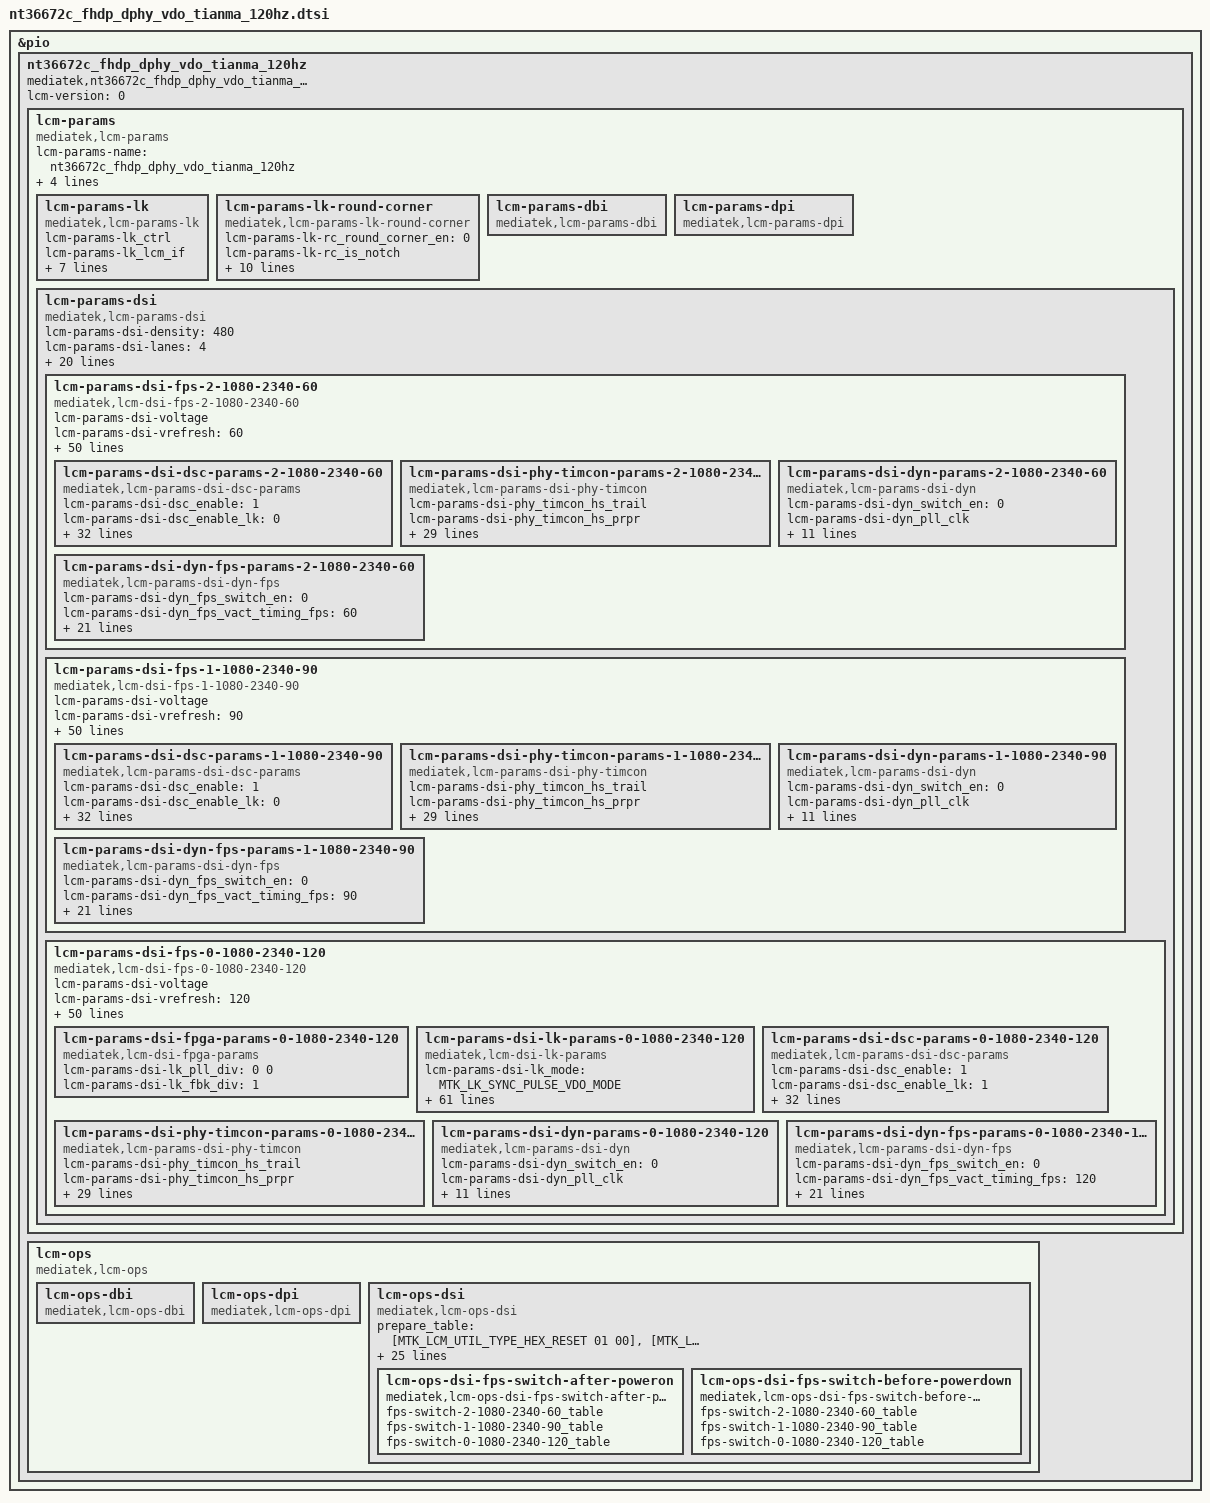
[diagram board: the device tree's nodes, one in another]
// SPDX-License-Identifier: GPL-2.0
/*
 * Device Tree defines for LCM settings
 * Copyright (c) 2021 MediaTek Inc.
 */

#include "mtk_lcm_settings.h"

&pio {
	nt36672c_fhdp_dphy_vdo_tianma_120hz: nt36672c_fhdp_dphy_vdo_tianma_120hz {
		compatible = "mediatek,nt36672c_fhdp_dphy_vdo_tianma_120hz";
		lcm-version = <0>;

		lcm-params{
			compatible = "mediatek,lcm-params";
			lcm-params-name = "nt36672c_fhdp_dphy_vdo_tianma_120hz";
			lcm-params-types = <MTK_LCM_FUNC_DSI>;
			lcm-params-resolution = <1080 2340>;
			lcm-params-physical_width = <68>;
			lcm-params-physical_height = <152>;

			/* lk support */
			lcm-params-lk {
				compatible = "mediatek,lcm-params-lk";
				lcm-params-lk_ctrl;
				lcm-params-lk_lcm_if;
				lcm-params-lk_lcm_cmd_if;
				lcm-params-lk_io_select_mode;
				lcm-params-lk_lcm_x;
				lcm-params-lk_lcm_y;
				lcm-params-lk_virtual_resolution = <0 0>;
				lcm-params-lk_od_table_size;
				lcm-params-lk_od_table;
			};

			lcm-params-lk-round-corner {
				compatible = "mediatek,lcm-params-lk-round-corner";
				lcm-params-lk-rc_round_corner_en = <0>;
				lcm-params-lk-rc_is_notch;
				lcm-params-lk-rc_full_content = <0>;
				lcm-params-lk-rc_width;
				lcm-params-lk-rc_height;
				lcm-params-lk-rc_width_bot;
				lcm-params-lk-rc_height_bot;
				lcm-params-lk-rc_top_size;
				lcm-params-lk-rc_top_size_left;
				lcm-params-lk-rc_top_size_right;
				lcm-params-lk-rc_bottom_size;
				lcm-params-lk-rc_pattern_name;
			};

			lcm-params-dbi {
				compatible = "mediatek,lcm-params-dbi";
				/* future reserved for dbi interfaces */
			};

			lcm-params-dpi {
				compatible = "mediatek,lcm-params-dpi";
				/* future reserved for dpi interfaces */
			};

			lcm-params-dsi {
				compatible = "mediatek,lcm-params-dsi";
				lcm-params-dsi-density = <480>;
				lcm-params-dsi-lanes = <4>;
				lcm-params-dsi-format = <MTK_MIPI_DSI_FMT_RGB888>;
				lcm-params-dsi-phy_type = <MTK_LCM_MIPI_DPHY>;
				lcm-params-dsi-mode_flags = <MTK_MIPI_DSI_MODE_VIDEO>,
						<MTK_MIPI_DSI_MODE_VIDEO_SYNC_PULSE>,
						<MTK_MIPI_DSI_MODE_LPM>,
						<MTK_MIPI_DSI_MODE_EOT_PACKET>,
						<MTK_MIPI_DSI_CLOCK_NON_CONTINUOUS>;
				lcm-params-dsi-mode_flags_doze_on;
				lcm-params-dsi-mode_flags_doze_off;

				lcm-params-dsi-need_fake_resolution;
				lcm-params-dsi-fake_resolution = <1080 2340>;

				lcm_gpio_list = <&pio 42 0>, /* gpio list*/
					<&pio 28 0>,
					<&pio 29 0>;
				pinctrl-names = "gpio1", "gpio2", "gpio3";
				pinctrl-0;
				pinctrl-1;
				pinctrl-2;
				status = "okay";

				lcm-params-dsi-default_mode = <0>;
				lcm-params-dsi-mode_count = <3>;
				lcm-params-dsi-mode_list =
					<0 1080 2340 120>,
					<1 1080 2340 90>,
					<2 1080 2340 60>;

				lcm-params-dsi-fps-2-1080-2340-60 {
					compatible = "mediatek,lcm-dsi-fps-2-1080-2340-60";
					lcm-params-dsi-voltage;

					/* drm_display_mode */
					lcm-params-dsi-vrefresh = <60>;
					lcm-params-dsi-vertical_sync_active = <10>;
					lcm-params-dsi-vertical_backporch = <25>;
					lcm-params-dsi-vertical_frontporch = <2380>;
					lcm-params-dsi-vertical_active_line = <2340>;
					lcm-params-dsi-horizontal_sync_active = <20>;
					lcm-params-dsi-horizontal_backporch = <80>;
					lcm-params-dsi-horizontal_frontporch = <80>;
					lcm-params-dsi-horizontal_active_pixel = <1080>;
					lcm-params-dsi-pixel_clock = <361519>;
					lcm-params-dsi-hskew;
					lcm-params-dsi-vscan;

					/* mtk_panel_params */
					lcm-params-dsi-pll_clock = <535>;
					lcm-params-dsi-data_rate = <1070>;
					lcm-params-dsi-vfp_for_low_power = <4205>;
					lcm-params-dsi-ssc_disable;
					lcm-params-dsi-ssc_range;
					lcm-params-dsi-lcm_color_mode;
					lcm-params-dsi-min_luminance;
					lcm-params-dsi-average_luminance;
					lcm-params-dsi-max_luminance;
					lcm-params-dsi-round_corner_en = <0>;
					lcm-params-dsi-corner_pattern_height;
					lcm-params-dsi-corner_pattern_height_bot;
					lcm-params-dsi-corner_pattern_tp_size;
					lcm-params-dsi-corner_pattern_tp_size_left;
					lcm-params-dsi-corner_pattern_tp_size_right;
					lcm-params-dsi-corner_pattern_name;
					lcm-params-dsi-physical_width_um = <68364>;
					lcm-params-dsi-physical_height_um = <152300>;
					lcm-params-dsi-output_mode =
						<MTK_LCM_PANEL_DSC_SINGLE_PORT>;
					lcm-params-dsi-lcm_cmd_if;
					lcm-params-dsi-hbm_en_time;
					lcm-params-dsi-hbm_dis_time;
					lcm-params-dsi-lcm_index;
					lcm-params-dsi-wait_sof_before_dec_vfp;
					lcm-params-dsi-doze_delay;
					lcm-params-dsi-lfr_enable = <1>;
					lcm-params-dsi-lfr_minimum_fps = <60>;
					lcm-params-dsi-msync2_enable;
					lcm-params-dsi-max_vfp_for_msync;

					/* lane swap */
					lcm-params-dsi-lane_swap_en;
					lcm-params-dsi-lane_swap0;
					lcm-params-dsi-lane_swap1;

					/* esd check table */
					lcm-params-dsi-cust_esd_check = <1>;
					lcm-params-dsi-esd_check_enable = <1>;
					lcm-params-dsi-lcm_esd_check_table0 = [0A 01 9C];
					lcm-params-dsi-lcm_esd_check_table1;
					lcm-params-dsi-lcm_esd_check_table2;

					lcm-params-dsi-dsc-params-2-1080-2340-60 {
						compatible =
							"mediatek,lcm-params-dsi-dsc-params";
						lcm-params-dsi-dsc_enable = <1>;
						lcm-params-dsi-dsc_enable_lk = <0>;
						lcm-params-dsi-dsc_ver = <17>;
						lcm-params-dsi-dsc_slice_mode = <1>;
						lcm-params-dsi-dsc_rgb_swap = <0>;
						lcm-params-dsi-dsc_cfg = <34>;
						lcm-params-dsi-dsc_rct_on = <1>;
						lcm-params-dsi-dsc_bit_per_channel = <8>;
						lcm-params-dsi-dsc_line_buf_depth = <9>;
						lcm-params-dsi-dsc_bp_enable = <1>;
						lcm-params-dsi-dsc_bit_per_pixel = <128>;
						lcm-params-dsi-dsc_pic_height = <2340>;
						lcm-params-dsi-dsc_pic_width = <1080>;
						lcm-params-dsi-dsc_slice_height = <20>;
						lcm-params-dsi-dsc_slice_width = <540>;
						lcm-params-dsi-dsc_chunk_size = <540>;
						lcm-params-dsi-dsc_xmit_delay = <512>;
						lcm-params-dsi-dsc_dec_delay = <526>;
						lcm-params-dsi-dsc_scale_value = <32>;
						lcm-params-dsi-dsc_increment_interval = <488>;
						lcm-params-dsi-dsc_decrement_interval = <7>;
						lcm-params-dsi-dsc_line_bpg_offset = <12>;
						lcm-params-dsi-dsc_nfl_bpg_offset = <1294>;
						lcm-params-dsi-dsc_slice_bpg_offset = <1302>;
						lcm-params-dsi-dsc_initial_offset = <6144>;
						lcm-params-dsi-dsc_final_offset = <4336>;
						lcm-params-dsi-dsc_flatness_minqp = <3>;
						lcm-params-dsi-dsc_flatness_maxqp = <12>;
						lcm-params-dsi-dsc_rc_model_size = <8192>;
						lcm-params-dsi-dsc_rc_edge_factor = <6>;
						lcm-params-dsi-dsc_rc_quant_incr_limit0 = <11>;
						lcm-params-dsi-dsc_rc_quant_incr_limit1 = <11>;
						lcm-params-dsi-dsc_rc_tgt_offset_hi = <3>;
						lcm-params-dsi-dsc_rc_tgt_offset_lo = <3>;
					};

					lcm-params-dsi-phy-timcon-params-2-1080-2340-60 {
						compatible =
							"mediatek,lcm-params-dsi-phy-timcon";
						lcm-params-dsi-phy_timcon_hs_trail;
						lcm-params-dsi-phy_timcon_hs_prpr;
						lcm-params-dsi-phy_timcon_hs_zero;
						lcm-params-dsi-phy_timcon_lpx;
						lcm-params-dsi-phy_timcon_ta_get;
						lcm-params-dsi-phy_timcon_ta_sure;
						lcm-params-dsi-phy_timcon_ta_go;
						lcm-params-dsi-phy_timcon_da_hs_exit;
						lcm-params-dsi-phy_timcon_clk_trail;
						lcm-params-dsi-phy_timcon_cont_det;
						lcm-params-dsi-phy_timcon_da_hs_sync;
						lcm-params-dsi-phy_timcon_clk_zero;
						lcm-params-dsi-phy_timcon_clk_prpr;
						lcm-params-dsi-phy_timcon_clk_exit;
						lcm-params-dsi-phy_timcon_clk_post;

						/* lk support */
						lcm-params-dsi-phy_timcon_lk_hs_trail;
						lcm-params-dsi-phy_timcon_lk_hs_zero;
						lcm-params-dsi-phy_timcon_lk_hs_prpr = <10>;
						lcm-params-dsi-phy_timcon_lk_lpx;
						lcm-params-dsi-phy_timcon_lk_ta_sack;
						lcm-params-dsi-phy_timcon_lk_ta_get;
						lcm-params-dsi-phy_timcon_lk_ta_sure;
						lcm-params-dsi-phy_timcon_lk_ta_go;
						lcm-params-dsi-phy_timcon_lk_clk_trail;
						lcm-params-dsi-phy_timcon_lk_clk_zero;
						lcm-params-dsi-phy_timcon_lk_lpx_wait;
						lcm-params-dsi-phy_timcon_lk_cont_det;
						lcm-params-dsi-phy_timcon_lk_clk_hs_prpr;
						lcm-params-dsi-phy_timcon_lk_clk_hs_post;
						lcm-params-dsi-phy_timcon_lk_da_hs_exit;
						lcm-params-dsi-phy_timcon_lk_clk_hs_exit;
					};

					lcm-params-dsi-dyn-params-2-1080-2340-60 {
						compatible =
							"mediatek,lcm-params-dsi-dyn";
						lcm-params-dsi-dyn_switch_en = <0>;
						lcm-params-dsi-dyn_pll_clk;
						lcm-params-dsi-dyn_data_rate = <1070>;
						lcm-params-dsi-dyn_vsa;
						lcm-params-dsi-dyn_vbp;
						lcm-params-dsi-dyn_vfp = <2528>;
						lcm-params-dsi-dyn_vfp_lp_dyn = <4178>;
						lcm-params-dsi-dyn_vac;
						lcm-params-dsi-dyn_hsa;
						lcm-params-dsi-dyn_hbp;
						lcm-params-dsi-dyn_hfp;
						lcm-params-dsi-dyn_hac;
						lcm-params-dsi-dyn_max_vfp_for_msync_dyn;
					};

					lcm-params-dsi-dyn-fps-params-2-1080-2340-60 {
						compatible =
							"mediatek,lcm-params-dsi-dyn-fps";
						lcm-params-dsi-dyn_fps_switch_en = <0>;
						lcm-params-dsi-dyn_fps_vact_timing_fps = <60>;
						lcm-params-dsi-dyn_fps_data_rate;
						lcm-params-dsi-dyn_fps_dfps_cmd_table0;
						lcm-params-dsi-dyn_fps_dfps_cmd_table1;
						lcm-params-dsi-dyn_fps_dfps_cmd_table2;
						lcm-params-dsi-dyn_fps_dfps_cmd_table3;
						lcm-params-dsi-dyn_fps_dfps_cmd_table4;
						lcm-params-dsi-dyn_fps_dfps_cmd_table5;
						lcm-params-dsi-dyn_fps_dfps_cmd_table6;
						lcm-params-dsi-dyn_fps_dfps_cmd_table7;
						lcm-params-dsi-dyn_fps_dfps_cmd_table8;
						lcm-params-dsi-dyn_fps_dfps_cmd_table9;
						lcm-params-dsi-dyn_fps_dfps_cmd_table10;
						lcm-params-dsi-dyn_fps_dfps_cmd_table11;
						lcm-params-dsi-dyn_fps_dfps_cmd_table12;
						lcm-params-dsi-dyn_fps_dfps_cmd_table13;
						lcm-params-dsi-dyn_fps_dfps_cmd_table14;
						lcm-params-dsi-dyn_fps_dfps_cmd_table15;
						lcm-params-dsi-dyn_fps_dfps_cmd_table16;
						lcm-params-dsi-dyn_fps_dfps_cmd_table17;
						lcm-params-dsi-dyn_fps_dfps_cmd_table18;
						lcm-params-dsi-dyn_fps_dfps_cmd_table19;
					};
				};

				lcm-params-dsi-fps-1-1080-2340-90 {
					compatible = "mediatek,lcm-dsi-fps-1-1080-2340-90";
					lcm-params-dsi-voltage;

					/* drm_display_mode */
					lcm-params-dsi-vrefresh = <90>;
					lcm-params-dsi-vertical_sync_active = <10>;
					lcm-params-dsi-vertical_backporch = <25>;
					lcm-params-dsi-vertical_frontporch = <810>;
					lcm-params-dsi-vertical_active_line = <2340>;
					lcm-params-dsi-horizontal_sync_active = <20>;
					lcm-params-dsi-horizontal_backporch = <80>;
					lcm-params-dsi-horizontal_frontporch = <80>;
					lcm-params-dsi-horizontal_active_pixel = <1080>;
					lcm-params-dsi-pixel_clock = <361519>;
					lcm-params-dsi-hskew;
					lcm-params-dsi-vscan;

					/* mtk_panel_params */
					lcm-params-dsi-pll_clock = <535>;
					lcm-params-dsi-data_rate = <1070>;
					lcm-params-dsi-vfp_for_low_power = <2546>;
					lcm-params-dsi-ssc_disable;
					lcm-params-dsi-ssc_range;
					lcm-params-dsi-lcm_color_mode;
					lcm-params-dsi-min_luminance;
					lcm-params-dsi-average_luminance;
					lcm-params-dsi-max_luminance;
					lcm-params-dsi-round_corner_en = <0>;
					lcm-params-dsi-corner_pattern_height;
					lcm-params-dsi-corner_pattern_height_bot;
					lcm-params-dsi-corner_pattern_tp_size;
					lcm-params-dsi-corner_pattern_tp_size_left;
					lcm-params-dsi-corner_pattern_tp_size_right;
					lcm-params-dsi-corner_pattern_name;
					lcm-params-dsi-physical_width_um = <68364>;
					lcm-params-dsi-physical_height_um = <152300>;
					lcm-params-dsi-output_mode =
						<MTK_LCM_PANEL_DSC_SINGLE_PORT>;
					lcm-params-dsi-lcm_cmd_if;
					lcm-params-dsi-hbm_en_time;
					lcm-params-dsi-hbm_dis_time;
					lcm-params-dsi-lcm_index;
					lcm-params-dsi-wait_sof_before_dec_vfp;
					lcm-params-dsi-doze_delay;
					lcm-params-dsi-lfr_enable = <1>;
					lcm-params-dsi-lfr_minimum_fps = <60>;
					lcm-params-dsi-msync2_enable;
					lcm-params-dsi-max_vfp_for_msync;

					/* lane swap */
					lcm-params-dsi-lane_swap_en;
					lcm-params-dsi-lane_swap0;
					lcm-params-dsi-lane_swap1;

					/* esd check table */
					lcm-params-dsi-cust_esd_check = <1>;
					lcm-params-dsi-esd_check_enable = <1>;
					lcm-params-dsi-lcm_esd_check_table0 = [0A 01 9C];
					lcm-params-dsi-lcm_esd_check_table1;
					lcm-params-dsi-lcm_esd_check_table2;

					lcm-params-dsi-dsc-params-1-1080-2340-90 {
						compatible =
							"mediatek,lcm-params-dsi-dsc-params";
						lcm-params-dsi-dsc_enable = <1>;
						lcm-params-dsi-dsc_enable_lk = <0>;
						lcm-params-dsi-dsc_ver = <17>;
						lcm-params-dsi-dsc_slice_mode = <1>;
						lcm-params-dsi-dsc_rgb_swap = <0>;
						lcm-params-dsi-dsc_cfg = <34>;
						lcm-params-dsi-dsc_rct_on = <1>;
						lcm-params-dsi-dsc_bit_per_channel = <8>;
						lcm-params-dsi-dsc_line_buf_depth = <9>;
						lcm-params-dsi-dsc_bp_enable = <1>;
						lcm-params-dsi-dsc_bit_per_pixel = <128>;
						lcm-params-dsi-dsc_pic_height = <2340>;
						lcm-params-dsi-dsc_pic_width = <1080>;
						lcm-params-dsi-dsc_slice_height = <20>;
						lcm-params-dsi-dsc_slice_width = <540>;
						lcm-params-dsi-dsc_chunk_size = <540>;
						lcm-params-dsi-dsc_xmit_delay = <512>;
						lcm-params-dsi-dsc_dec_delay = <526>;
						lcm-params-dsi-dsc_scale_value = <32>;
						lcm-params-dsi-dsc_increment_interval = <488>;
						lcm-params-dsi-dsc_decrement_interval = <7>;
						lcm-params-dsi-dsc_line_bpg_offset = <12>;
						lcm-params-dsi-dsc_nfl_bpg_offset = <1294>;
						lcm-params-dsi-dsc_slice_bpg_offset = <1302>;
						lcm-params-dsi-dsc_initial_offset = <6144>;
						lcm-params-dsi-dsc_final_offset = <4336>;
						lcm-params-dsi-dsc_flatness_minqp = <3>;
						lcm-params-dsi-dsc_flatness_maxqp = <12>;
						lcm-params-dsi-dsc_rc_model_size = <8192>;
						lcm-params-dsi-dsc_rc_edge_factor = <6>;
						lcm-params-dsi-dsc_rc_quant_incr_limit0 = <11>;
						lcm-params-dsi-dsc_rc_quant_incr_limit1 = <11>;
						lcm-params-dsi-dsc_rc_tgt_offset_hi = <3>;
						lcm-params-dsi-dsc_rc_tgt_offset_lo = <3>;
					};

					lcm-params-dsi-phy-timcon-params-1-1080-2340-90 {
						compatible =
							"mediatek,lcm-params-dsi-phy-timcon";
						lcm-params-dsi-phy_timcon_hs_trail;
						lcm-params-dsi-phy_timcon_hs_prpr;
						lcm-params-dsi-phy_timcon_hs_zero;
						lcm-params-dsi-phy_timcon_lpx;
						lcm-params-dsi-phy_timcon_ta_get;
						lcm-params-dsi-phy_timcon_ta_sure;
						lcm-params-dsi-phy_timcon_ta_go;
						lcm-params-dsi-phy_timcon_da_hs_exit;
						lcm-params-dsi-phy_timcon_clk_trail;
						lcm-params-dsi-phy_timcon_cont_det;
						lcm-params-dsi-phy_timcon_da_hs_sync;
						lcm-params-dsi-phy_timcon_clk_zero;
						lcm-params-dsi-phy_timcon_clk_prpr;
						lcm-params-dsi-phy_timcon_clk_exit;
						lcm-params-dsi-phy_timcon_clk_post;

						/* lk support */
						lcm-params-dsi-phy_timcon_lk_hs_trail;
						lcm-params-dsi-phy_timcon_lk_hs_zero;
						lcm-params-dsi-phy_timcon_lk_hs_prpr;
						lcm-params-dsi-phy_timcon_lk_lpx;
						lcm-params-dsi-phy_timcon_lk_ta_sack;
						lcm-params-dsi-phy_timcon_lk_ta_get;
						lcm-params-dsi-phy_timcon_lk_ta_sure;
						lcm-params-dsi-phy_timcon_lk_ta_go;
						lcm-params-dsi-phy_timcon_lk_clk_trail;
						lcm-params-dsi-phy_timcon_lk_clk_zero;
						lcm-params-dsi-phy_timcon_lk_lpx_wait;
						lcm-params-dsi-phy_timcon_lk_cont_det;
						lcm-params-dsi-phy_timcon_lk_clk_hs_prpr;
						lcm-params-dsi-phy_timcon_lk_clk_hs_post;
						lcm-params-dsi-phy_timcon_lk_da_hs_exit;
						lcm-params-dsi-phy_timcon_lk_clk_hs_exit;
					};

					lcm-params-dsi-dyn-params-1-1080-2340-90 {
						compatible =
							"mediatek,lcm-params-dsi-dyn";
						lcm-params-dsi-dyn_switch_en = <0>;
						lcm-params-dsi-dyn_pll_clk;
						lcm-params-dsi-dyn_data_rate = <1070>;
						lcm-params-dsi-dyn_vsa;
						lcm-params-dsi-dyn_vbp;
						lcm-params-dsi-dyn_vfp = <879>;
						lcm-params-dsi-dyn_vfp_lp_dyn;
						lcm-params-dsi-dyn_vac;
						lcm-params-dsi-dyn_hsa;
						lcm-params-dsi-dyn_hbp;
						lcm-params-dsi-dyn_hfp;
						lcm-params-dsi-dyn_hac;
						lcm-params-dsi-dyn_max_vfp_for_msync_dyn;
					};

					lcm-params-dsi-dyn-fps-params-1-1080-2340-90 {
						compatible =
							"mediatek,lcm-params-dsi-dyn-fps";
						lcm-params-dsi-dyn_fps_switch_en = <0>;
						lcm-params-dsi-dyn_fps_vact_timing_fps = <90>;
						lcm-params-dsi-dyn_fps_data_rate;
						lcm-params-dsi-dyn_fps_dfps_cmd_table0;
						lcm-params-dsi-dyn_fps_dfps_cmd_table1;
						lcm-params-dsi-dyn_fps_dfps_cmd_table2;
						lcm-params-dsi-dyn_fps_dfps_cmd_table3;
						lcm-params-dsi-dyn_fps_dfps_cmd_table4;
						lcm-params-dsi-dyn_fps_dfps_cmd_table5;
						lcm-params-dsi-dyn_fps_dfps_cmd_table6;
						lcm-params-dsi-dyn_fps_dfps_cmd_table7;
						lcm-params-dsi-dyn_fps_dfps_cmd_table8;
						lcm-params-dsi-dyn_fps_dfps_cmd_table9;
						lcm-params-dsi-dyn_fps_dfps_cmd_table10;
						lcm-params-dsi-dyn_fps_dfps_cmd_table11;
						lcm-params-dsi-dyn_fps_dfps_cmd_table12;
						lcm-params-dsi-dyn_fps_dfps_cmd_table13;
						lcm-params-dsi-dyn_fps_dfps_cmd_table14;
						lcm-params-dsi-dyn_fps_dfps_cmd_table15;
						lcm-params-dsi-dyn_fps_dfps_cmd_table16;
						lcm-params-dsi-dyn_fps_dfps_cmd_table17;
						lcm-params-dsi-dyn_fps_dfps_cmd_table18;
						lcm-params-dsi-dyn_fps_dfps_cmd_table19;
					};
				};

				lcm-params-dsi-fps-0-1080-2340-120 {
					compatible = "mediatek,lcm-dsi-fps-0-1080-2340-120";
					lcm-params-dsi-voltage;

					/* drm_display_mode */
					lcm-params-dsi-vrefresh = <120>;
					lcm-params-dsi-vertical_sync_active = <10>;
					lcm-params-dsi-vertical_backporch = <25>;
					lcm-params-dsi-vertical_frontporch = <16>;
					lcm-params-dsi-vertical_active_line = <2340>;
					lcm-params-dsi-horizontal_sync_active = <20>;
					lcm-params-dsi-horizontal_backporch = <80>;
					lcm-params-dsi-horizontal_frontporch = <80>;
					lcm-params-dsi-horizontal_active_pixel = <1080>;
					lcm-params-dsi-pixel_clock = <361519>;
					lcm-params-dsi-hskew;
					lcm-params-dsi-vscan;

					/* mtk_panel_params */
					lcm-params-dsi-pll_clock = <535>;
					lcm-params-dsi-data_rate = <1070>;
					lcm-params-dsi-vfp_for_low_power = <2546>;
					lcm-params-dsi-ssc_disable;
					lcm-params-dsi-ssc_range;
					lcm-params-dsi-lcm_color_mode;
					lcm-params-dsi-min_luminance;
					lcm-params-dsi-average_luminance;
					lcm-params-dsi-max_luminance;
					lcm-params-dsi-round_corner_en = <0>;
					lcm-params-dsi-corner_pattern_height;
					lcm-params-dsi-corner_pattern_height_bot;
					lcm-params-dsi-corner_pattern_tp_size;
					lcm-params-dsi-corner_pattern_tp_size_left;
					lcm-params-dsi-corner_pattern_tp_size_right;
					lcm-params-dsi-corner_pattern_name;
					lcm-params-dsi-physical_width_um = <68364>;
					lcm-params-dsi-physical_height_um = <152300>;
					lcm-params-dsi-output_mode =
						<MTK_LCM_PANEL_DSC_SINGLE_PORT>;
					lcm-params-dsi-lcm_cmd_if;
					lcm-params-dsi-hbm_en_time;
					lcm-params-dsi-hbm_dis_time;
					lcm-params-dsi-lcm_index;
					lcm-params-dsi-wait_sof_before_dec_vfp;
					lcm-params-dsi-doze_delay;
					lcm-params-dsi-lfr_enable = <1>;
					lcm-params-dsi-lfr_minimum_fps = <60>;
					lcm-params-dsi-msync2_enable;
					lcm-params-dsi-max_vfp_for_msync;

					/* lane swap */
					lcm-params-dsi-lane_swap_en;
					lcm-params-dsi-lane_swap0;
					lcm-params-dsi-lane_swap1;

					/* esd check table */
					lcm-params-dsi-cust_esd_check = <1>;
					lcm-params-dsi-esd_check_enable = <1>;
					lcm-params-dsi-lcm_esd_check_table0 = [0A 01 9C];
					lcm-params-dsi-lcm_esd_check_table1;
					lcm-params-dsi-lcm_esd_check_table2;

					/* fpga support */
					lcm-params-dsi-fpga-params-0-1080-2340-120 {
						compatible = "mediatek,lcm-dsi-fpga-params";

						lcm-params-dsi-lk_pll_div = <0 0>;
						lcm-params-dsi-lk_fbk_div = <1>;
					};

					/* lk support */
					lcm-params-dsi-lk-params-0-1080-2340-120 {
						compatible = "mediatek,lcm-dsi-lk-params";
						lcm-params-dsi-lk_mode =
							<MTK_LK_SYNC_PULSE_VDO_MODE>;
						lcm-params-dsi-lk_switch_mode = <MTK_LK_CMD_MODE>;
						lcm-params-dsi-lk_switch_mode_enable = <0>;
						lcm-params-dsi-lk_dsi_wmem_conti;
						lcm-params-dsi-lk_dsi_rmem_conti;
						lcm-params-dsi-lk_vc_num;
						lcm-params-dsi-lk_data_format =
							<MTK_LCM_COLOR_ORDER_RGB>,
							<MTK_LCM_DSI_TRANS_SEQ_MSB_FIRST>,
							<MTK_LCM_DSI_PADDING_ON_LSB>,
							<MTK_LCM_DSI_FORMAT_RGB888>;
						lcm-params-dsi-lk_intermediat_buffer_num;
						lcm-params-dsi-lk_ps =
							<MTK_LCM_PACKED_PS_24BIT_RGB888>;
						lcm-params-dsi-lk_word_count;
						lcm-params-dsi-lk_packet_size = <256>;

						lcm-params-dsi-lk_horizontal_blanking_pixel;
						lcm-params-dsi-lk_bllp;
						lcm-params-dsi-lk_line_byte;
						lcm-params-dsi-lk_horizontal_sync_active_byte;
						lcm-params-dsi-lk_horizontal_backporch_byte;
						lcm-params-dsi-lk_horizontal_frontporch_byte;
						lcm-params-dsi-lk_rgb_byte;
						lcm-params-dsi-lk_horizontal_sync_active_word_count;
						lcm-params-dsi-lk_horizontal_backporch_word_count;
						lcm-params-dsi-lk_horizontal_frontporch_word_count;
						lcm-params-dsi-lk_pll_select;
						lcm-params-dsi-lk_pll_div;
						lcm-params-dsi-lk_fbk_div;
						lcm-params-dsi-lk_fbk_sel;
						lcm-params-dsi-lk_rg = <0 0 0>;
						lcm-params-dsi-lk_dsi_clock;
						lcm-params-dsi-lk_ssc_disable = <1>;
						lcm-params-dsi-lk_ssc_range;
						lcm-params-dsi-lk_compatibility_for_nvk;
						lcm-params-dsi-lk_cont_clock;
						lcm-params-dsi-lk_ufoe_enable;
						lcm-params-dsi-lk_ufoe_params = <0 0 0 0>;
						lcm-params-dsi-lk_edp_panel;
						lcm-params-dsi-lk_lcm_int_te_monitor;
						lcm-params-dsi-lk_lcm_int_te_period;
						lcm-params-dsi-lk_lcm_ext_te_monitor;
						lcm-params-dsi-lk_lcm_ext_te_period;
						lcm-params-dsi-lk_noncont_clock;
						lcm-params-dsi-lk_noncont_clock_period;
						lcm-params-dsi-lk_clk_lp_per_line_enable = <0>;
						lcm-params-dsi-lk_dual_dsi_type;
						lcm-params-dsi-lk_mixmode_enable;
						lcm-params-dsi-lk_mixmode_mipi_clock;
						lcm-params-dsi-lk_pwm_fps;
						lcm-params-dsi-lk_pll_clock_lp;
						lcm-params-dsi-lk_ulps_sw_enable;
						lcm-params-dsi-lk_null_packet_en;
						lcm-params-dsi-lk_vact_fps = <120>;
						lcm-params-dsi-lk_send_frame_enable;
						lcm-params-dsi-lk_lfr_enable;
						lcm-params-dsi-lk_lfr_mode;
						lcm-params-dsi-lk_lfr_type;
						lcm-params-dsi-lk_lfr_skip_num;
						lcm-params-dsi-lk_ext_te_edge;
						lcm-params-dsi-lk_eint_disable;
						lcm-params-dsi-lk_phy_sel = <0 0 0 0>;
					};

					lcm-params-dsi-dsc-params-0-1080-2340-120 {
						compatible =
							"mediatek,lcm-params-dsi-dsc-params";
						lcm-params-dsi-dsc_enable = <1>;
						lcm-params-dsi-dsc_enable_lk = <1>;
						lcm-params-dsi-dsc_ver = <17>;
						lcm-params-dsi-dsc_slice_mode = <1>;
						lcm-params-dsi-dsc_rgb_swap = <0>;
						lcm-params-dsi-dsc_cfg = <34>;
						lcm-params-dsi-dsc_rct_on = <1>;
						lcm-params-dsi-dsc_bit_per_channel = <8>;
						lcm-params-dsi-dsc_line_buf_depth = <9>;
						lcm-params-dsi-dsc_bp_enable = <1>;
						lcm-params-dsi-dsc_bit_per_pixel = <128>;
						lcm-params-dsi-dsc_pic_height = <2340>;
						lcm-params-dsi-dsc_pic_width = <1080>;
						lcm-params-dsi-dsc_slice_height = <20>;
						lcm-params-dsi-dsc_slice_width = <540>;
						lcm-params-dsi-dsc_chunk_size = <540>;
						lcm-params-dsi-dsc_xmit_delay = <512>;
						lcm-params-dsi-dsc_dec_delay = <526>;
						lcm-params-dsi-dsc_scale_value = <32>;
						lcm-params-dsi-dsc_increment_interval = <488>;
						lcm-params-dsi-dsc_decrement_interval = <7>;
						lcm-params-dsi-dsc_line_bpg_offset = <12>;
						lcm-params-dsi-dsc_nfl_bpg_offset = <1294>;
						lcm-params-dsi-dsc_slice_bpg_offset = <1302>;
						lcm-params-dsi-dsc_initial_offset = <6144>;
						lcm-params-dsi-dsc_final_offset = <4336>;
						lcm-params-dsi-dsc_flatness_minqp = <3>;
						lcm-params-dsi-dsc_flatness_maxqp = <12>;
						lcm-params-dsi-dsc_rc_model_size = <8192>;
						lcm-params-dsi-dsc_rc_edge_factor = <6>;
						lcm-params-dsi-dsc_rc_quant_incr_limit0 = <11>;
						lcm-params-dsi-dsc_rc_quant_incr_limit1 = <11>;
						lcm-params-dsi-dsc_rc_tgt_offset_hi = <3>;
						lcm-params-dsi-dsc_rc_tgt_offset_lo = <3>;
					};

					lcm-params-dsi-phy-timcon-params-0-1080-2340-120 {
						compatible =
							"mediatek,lcm-params-dsi-phy-timcon";
						lcm-params-dsi-phy_timcon_hs_trail;
						lcm-params-dsi-phy_timcon_hs_prpr;
						lcm-params-dsi-phy_timcon_hs_zero;
						lcm-params-dsi-phy_timcon_lpx;
						lcm-params-dsi-phy_timcon_ta_get;
						lcm-params-dsi-phy_timcon_ta_sure;
						lcm-params-dsi-phy_timcon_ta_go;
						lcm-params-dsi-phy_timcon_da_hs_exit;
						lcm-params-dsi-phy_timcon_clk_trail;
						lcm-params-dsi-phy_timcon_cont_det;
						lcm-params-dsi-phy_timcon_da_hs_sync;
						lcm-params-dsi-phy_timcon_clk_zero;
						lcm-params-dsi-phy_timcon_clk_prpr;
						lcm-params-dsi-phy_timcon_clk_exit;
						lcm-params-dsi-phy_timcon_clk_post;

						/* lk support */
						lcm-params-dsi-phy_timcon_lk_hs_trail;
						lcm-params-dsi-phy_timcon_lk_hs_zero;
						lcm-params-dsi-phy_timcon_lk_hs_prpr = <10>;
						lcm-params-dsi-phy_timcon_lk_lpx;
						lcm-params-dsi-phy_timcon_lk_ta_sack;
						lcm-params-dsi-phy_timcon_lk_ta_get;
						lcm-params-dsi-phy_timcon_lk_ta_sure;
						lcm-params-dsi-phy_timcon_lk_ta_go;
						lcm-params-dsi-phy_timcon_lk_clk_trail;
						lcm-params-dsi-phy_timcon_lk_clk_zero;
						lcm-params-dsi-phy_timcon_lk_lpx_wait;
						lcm-params-dsi-phy_timcon_lk_cont_det;
						lcm-params-dsi-phy_timcon_lk_clk_hs_prpr;
						lcm-params-dsi-phy_timcon_lk_clk_hs_post;
						lcm-params-dsi-phy_timcon_lk_da_hs_exit;
						lcm-params-dsi-phy_timcon_lk_clk_hs_exit;
					};

					lcm-params-dsi-dyn-params-0-1080-2340-120 {
						compatible =
							"mediatek,lcm-params-dsi-dyn";
						lcm-params-dsi-dyn_switch_en = <0>;
						lcm-params-dsi-dyn_pll_clk;
						lcm-params-dsi-dyn_data_rate = <1070>;
						lcm-params-dsi-dyn_vsa;
						lcm-params-dsi-dyn_vbp;
						lcm-params-dsi-dyn_vfp;
						lcm-params-dsi-dyn_vfp_lp_dyn;
						lcm-params-dsi-dyn_vac;
						lcm-params-dsi-dyn_hsa;
						lcm-params-dsi-dyn_hbp;
						lcm-params-dsi-dyn_hfp;
						lcm-params-dsi-dyn_hac;
						lcm-params-dsi-dyn_max_vfp_for_msync_dyn;
					};

					lcm-params-dsi-dyn-fps-params-0-1080-2340-120 {
						compatible =
							"mediatek,lcm-params-dsi-dyn-fps";
						lcm-params-dsi-dyn_fps_switch_en = <0>;
						lcm-params-dsi-dyn_fps_vact_timing_fps = <120>;
						lcm-params-dsi-dyn_fps_data_rate;
						lcm-params-dsi-dyn_fps_dfps_cmd_table0;
						lcm-params-dsi-dyn_fps_dfps_cmd_table1;
						lcm-params-dsi-dyn_fps_dfps_cmd_table2;
						lcm-params-dsi-dyn_fps_dfps_cmd_table3;
						lcm-params-dsi-dyn_fps_dfps_cmd_table4;
						lcm-params-dsi-dyn_fps_dfps_cmd_table5;
						lcm-params-dsi-dyn_fps_dfps_cmd_table6;
						lcm-params-dsi-dyn_fps_dfps_cmd_table7;
						lcm-params-dsi-dyn_fps_dfps_cmd_table8;
						lcm-params-dsi-dyn_fps_dfps_cmd_table9;
						lcm-params-dsi-dyn_fps_dfps_cmd_table10;
						lcm-params-dsi-dyn_fps_dfps_cmd_table11;
						lcm-params-dsi-dyn_fps_dfps_cmd_table12;
						lcm-params-dsi-dyn_fps_dfps_cmd_table13;
						lcm-params-dsi-dyn_fps_dfps_cmd_table14;
						lcm-params-dsi-dyn_fps_dfps_cmd_table15;
						lcm-params-dsi-dyn_fps_dfps_cmd_table16;
						lcm-params-dsi-dyn_fps_dfps_cmd_table17;
						lcm-params-dsi-dyn_fps_dfps_cmd_table18;
						lcm-params-dsi-dyn_fps_dfps_cmd_table19;
					};
				};
			};
		};

		lcm-ops {
			compatible = "mediatek,lcm-ops";
			lcm-ops-dbi {
				compatible = "mediatek,lcm-ops-dbi";
				/* future reserved for dbi interfaces*/
			};

			lcm-ops-dpi {
				compatible = "mediatek,lcm-ops-dpi";
				/* future reserved for dpi interfaces*/
			};

			lcm-ops-dsi {
				compatible = "mediatek,lcm-ops-dsi";
				prepare_table = [MTK_LCM_UTIL_TYPE_HEX_RESET 01 00],
					[MTK_LCM_UTIL_TYPE_HEX_MDELAY 01 05],
					[MTK_LCM_UTIL_TYPE_HEX_RESET 01 01],
					[MTK_LCM_UTIL_TYPE_HEX_MDELAY 01 05],
					[MTK_LCM_UTIL_TYPE_HEX_RESET 01 00],
					[MTK_LCM_UTIL_TYPE_HEX_MDELAY 01 05],
					[MTK_LCM_UTIL_TYPE_HEX_RESET 01 01],
					[MTK_LCM_UTIL_TYPE_HEX_MDELAY 01 0f],
					[MTK_LCM_CMD_TYPE_HEX_WRITE_BUFFER 02 FF 10],
					[MTK_LCM_CMD_TYPE_HEX_WRITE_BUFFER 02 FB 01],
					[MTK_LCM_CMD_TYPE_HEX_WRITE_BUFFER 06],
						[3B 03 0A 0A 04 04],
					[MTK_LCM_CMD_TYPE_HEX_WRITE_BUFFER 02 B0 00],
					[MTK_LCM_CMD_TYPE_HEX_WRITE_BUFFER 11],
						[C1 89 28 00 14 02 00 02 0E 01],
						[E8 00 07 05 0E 05 16],
					[MTK_LCM_CMD_TYPE_HEX_WRITE_BUFFER 03 C2 1B A0],
					[MTK_LCM_CMD_TYPE_HEX_WRITE_BUFFER 02 FF 20],
					[MTK_LCM_CMD_TYPE_HEX_WRITE_BUFFER 02 FB 01],
					[MTK_LCM_CMD_TYPE_HEX_WRITE_BUFFER 02 01 66],
					[MTK_LCM_CMD_TYPE_HEX_WRITE_BUFFER 02 06 3C],
					[MTK_LCM_CMD_TYPE_HEX_WRITE_BUFFER 02 07 28],
					[MTK_LCM_CMD_TYPE_HEX_WRITE_BUFFER 02 69 EA],
					[MTK_LCM_CMD_TYPE_HEX_WRITE_BUFFER 02 95 D1],
					[MTK_LCM_CMD_TYPE_HEX_WRITE_BUFFER 02 96 D1],
					[MTK_LCM_CMD_TYPE_HEX_WRITE_BUFFER 02 F2 64],
					[MTK_LCM_CMD_TYPE_HEX_WRITE_BUFFER 02 F4 64],
					[MTK_LCM_CMD_TYPE_HEX_WRITE_BUFFER 02 F6 64],
					[MTK_LCM_CMD_TYPE_HEX_WRITE_BUFFER 02 F8 64],
					[MTK_LCM_CMD_TYPE_HEX_WRITE_BUFFER 02 FF 24],
					[MTK_LCM_CMD_TYPE_HEX_WRITE_BUFFER 02 FB 01],
					[MTK_LCM_CMD_TYPE_HEX_WRITE_BUFFER 02 00 01],
					[MTK_LCM_CMD_TYPE_HEX_WRITE_BUFFER 02 01 0C],
					[MTK_LCM_CMD_TYPE_HEX_WRITE_BUFFER 02 02 0B],
					[MTK_LCM_CMD_TYPE_HEX_WRITE_BUFFER 02 03 0B],
					[MTK_LCM_CMD_TYPE_HEX_WRITE_BUFFER 02 04 2C],
					[MTK_LCM_CMD_TYPE_HEX_WRITE_BUFFER 02 05 2D],
					[MTK_LCM_CMD_TYPE_HEX_WRITE_BUFFER 02 06 2E],
					[MTK_LCM_CMD_TYPE_HEX_WRITE_BUFFER 02 07 2F],
					[MTK_LCM_CMD_TYPE_HEX_WRITE_BUFFER 02 08 30],
					[MTK_LCM_CMD_TYPE_HEX_WRITE_BUFFER 02 09 0F],
					[MTK_LCM_CMD_TYPE_HEX_WRITE_BUFFER 02 0A 10],
					[MTK_LCM_CMD_TYPE_HEX_WRITE_BUFFER 02 0B 24],
					[MTK_LCM_CMD_TYPE_HEX_WRITE_BUFFER 02 0C 24],
					[MTK_LCM_CMD_TYPE_HEX_WRITE_BUFFER 02 0D 18],
					[MTK_LCM_CMD_TYPE_HEX_WRITE_BUFFER 02 0E 16],
					[MTK_LCM_CMD_TYPE_HEX_WRITE_BUFFER 02 0F 14],
					[MTK_LCM_CMD_TYPE_HEX_WRITE_BUFFER 02 10 17],
					[MTK_LCM_CMD_TYPE_HEX_WRITE_BUFFER 02 11 15],
					[MTK_LCM_CMD_TYPE_HEX_WRITE_BUFFER 02 12 13],
					[MTK_LCM_CMD_TYPE_HEX_WRITE_BUFFER 02 13 24],
					[MTK_LCM_CMD_TYPE_HEX_WRITE_BUFFER 02 14 00],
					[MTK_LCM_CMD_TYPE_HEX_WRITE_BUFFER 02 15 00],
					[MTK_LCM_CMD_TYPE_HEX_WRITE_BUFFER 02 16 00],
					[MTK_LCM_CMD_TYPE_HEX_WRITE_BUFFER 02 17 20],
					[MTK_LCM_CMD_TYPE_HEX_WRITE_BUFFER 02 18 01],
					[MTK_LCM_CMD_TYPE_HEX_WRITE_BUFFER 02 19 0C],
					[MTK_LCM_CMD_TYPE_HEX_WRITE_BUFFER 02 1A 0B],
					[MTK_LCM_CMD_TYPE_HEX_WRITE_BUFFER 02 1B 0B],
					[MTK_LCM_CMD_TYPE_HEX_WRITE_BUFFER 02 1C 2C],
					[MTK_LCM_CMD_TYPE_HEX_WRITE_BUFFER 02 1D 2D],
					[MTK_LCM_CMD_TYPE_HEX_WRITE_BUFFER 02 1E 2E],
					[MTK_LCM_CMD_TYPE_HEX_WRITE_BUFFER 02 1F 2F],
					[MTK_LCM_CMD_TYPE_HEX_WRITE_BUFFER 02 20 30],
					[MTK_LCM_CMD_TYPE_HEX_WRITE_BUFFER 02 21 0F],
					[MTK_LCM_CMD_TYPE_HEX_WRITE_BUFFER 02 22 10],
					[MTK_LCM_CMD_TYPE_HEX_WRITE_BUFFER 02 23 24],
					[MTK_LCM_CMD_TYPE_HEX_WRITE_BUFFER 02 24 24],
					[MTK_LCM_CMD_TYPE_HEX_WRITE_BUFFER 02 25 18],
					[MTK_LCM_CMD_TYPE_HEX_WRITE_BUFFER 02 26 16],
					[MTK_LCM_CMD_TYPE_HEX_WRITE_BUFFER 02 27 14],
					[MTK_LCM_CMD_TYPE_HEX_WRITE_BUFFER 02 28 17],
					[MTK_LCM_CMD_TYPE_HEX_WRITE_BUFFER 02 29 15],
					[MTK_LCM_CMD_TYPE_HEX_WRITE_BUFFER 02 2A 13],
					[MTK_LCM_CMD_TYPE_HEX_WRITE_BUFFER 02 2B 24],
					[MTK_LCM_CMD_TYPE_HEX_WRITE_BUFFER 02 2D 00],
					[MTK_LCM_CMD_TYPE_HEX_WRITE_BUFFER 02 2F 00],
					[MTK_LCM_CMD_TYPE_HEX_WRITE_BUFFER 02 30 00],
					[MTK_LCM_CMD_TYPE_HEX_WRITE_BUFFER 02 31 20],
					[MTK_LCM_CMD_TYPE_HEX_WRITE_BUFFER 02 32 00],
					[MTK_LCM_CMD_TYPE_HEX_WRITE_BUFFER 02 34 10],
					[MTK_LCM_CMD_TYPE_HEX_WRITE_BUFFER 02 35 3C],
					[MTK_LCM_CMD_TYPE_HEX_WRITE_BUFFER 02 36 14],
					[MTK_LCM_CMD_TYPE_HEX_WRITE_BUFFER 02 4D 02],
					[MTK_LCM_CMD_TYPE_HEX_WRITE_BUFFER 02 4E 3A],
					[MTK_LCM_CMD_TYPE_HEX_WRITE_BUFFER 02 4F 3A],
					[MTK_LCM_CMD_TYPE_HEX_WRITE_BUFFER 02 53 3A],
					[MTK_LCM_CMD_TYPE_HEX_WRITE_BUFFER 02 79 11],
					[MTK_LCM_CMD_TYPE_HEX_WRITE_BUFFER 02 7A 82],
					[MTK_LCM_CMD_TYPE_HEX_WRITE_BUFFER 02 7B 8F],
					[MTK_LCM_CMD_TYPE_HEX_WRITE_BUFFER 02 82 13],
					[MTK_LCM_CMD_TYPE_HEX_WRITE_BUFFER 02 83 22],
					[MTK_LCM_CMD_TYPE_HEX_WRITE_BUFFER 02 84 31],
					[MTK_LCM_CMD_TYPE_HEX_WRITE_BUFFER 02 85 00],
					[MTK_LCM_CMD_TYPE_HEX_WRITE_BUFFER 02 86 00],
					[MTK_LCM_CMD_TYPE_HEX_WRITE_BUFFER 02 87 00],
					[MTK_LCM_CMD_TYPE_HEX_WRITE_BUFFER 02 90 13],
					[MTK_LCM_CMD_TYPE_HEX_WRITE_BUFFER 02 91 22],
					[MTK_LCM_CMD_TYPE_HEX_WRITE_BUFFER 02 92 31],
					[MTK_LCM_CMD_TYPE_HEX_WRITE_BUFFER 02 93 00],
					[MTK_LCM_CMD_TYPE_HEX_WRITE_BUFFER 02 94 00],
					[MTK_LCM_CMD_TYPE_HEX_WRITE_BUFFER 02 95 00],
					[MTK_LCM_CMD_TYPE_HEX_WRITE_BUFFER 02 9C F4],
					[MTK_LCM_CMD_TYPE_HEX_WRITE_BUFFER 02 9D 01],
					[MTK_LCM_CMD_TYPE_HEX_WRITE_BUFFER 02 D9 80],
					[MTK_LCM_CMD_TYPE_HEX_WRITE_BUFFER 02 A0 0F],
					[MTK_LCM_CMD_TYPE_HEX_WRITE_BUFFER 02 A2 0F],
					[MTK_LCM_CMD_TYPE_HEX_WRITE_BUFFER 02 A3 02],
					[MTK_LCM_CMD_TYPE_HEX_WRITE_BUFFER 02 C9 0C],
					[MTK_LCM_CMD_TYPE_HEX_WRITE_BUFFER 02 D1 34],
					[MTK_LCM_CMD_TYPE_HEX_WRITE_BUFFER 02 E9 02],
					[MTK_LCM_CMD_TYPE_HEX_WRITE_BUFFER 02 FF 25],
					[MTK_LCM_CMD_TYPE_HEX_WRITE_BUFFER 02 FB 01],
					[MTK_LCM_CMD_TYPE_HEX_WRITE_BUFFER 02 66 5D],
					[MTK_LCM_CMD_TYPE_HEX_WRITE_BUFFER 02 68 50],
					[MTK_LCM_CMD_TYPE_HEX_WRITE_BUFFER 02 69 60],
					[MTK_LCM_CMD_TYPE_HEX_WRITE_BUFFER 02 6B 00],
					[MTK_LCM_CMD_TYPE_HEX_WRITE_BUFFER 02 71 6D],
					[MTK_LCM_CMD_TYPE_HEX_WRITE_BUFFER 02 77 60],
					[MTK_LCM_CMD_TYPE_HEX_WRITE_BUFFER 02 79 40],
					[MTK_LCM_CMD_TYPE_HEX_WRITE_BUFFER 02 7E 25],
					[MTK_LCM_CMD_TYPE_HEX_WRITE_BUFFER 02 81 04],
					[MTK_LCM_CMD_TYPE_HEX_WRITE_BUFFER 02 84 34],
					[MTK_LCM_CMD_TYPE_HEX_WRITE_BUFFER 02 85 15],
					[MTK_LCM_CMD_TYPE_HEX_WRITE_BUFFER 02 8E 10],
					[MTK_LCM_CMD_TYPE_HEX_WRITE_BUFFER 02 C2 D2],
					[MTK_LCM_CMD_TYPE_HEX_WRITE_BUFFER 02 D6 80],
					[MTK_LCM_CMD_TYPE_HEX_WRITE_BUFFER 02 D7 02],
					[MTK_LCM_CMD_TYPE_HEX_WRITE_BUFFER 02 DA 00],
					[MTK_LCM_CMD_TYPE_HEX_WRITE_BUFFER 02 DD 02],
					[MTK_LCM_CMD_TYPE_HEX_WRITE_BUFFER 02 E0 00],
					[MTK_LCM_CMD_TYPE_HEX_WRITE_BUFFER 02 EF 00],
					[MTK_LCM_CMD_TYPE_HEX_WRITE_BUFFER 02 F1 04],
					[MTK_LCM_CMD_TYPE_HEX_WRITE_BUFFER 02 FF 26],
					[MTK_LCM_CMD_TYPE_HEX_WRITE_BUFFER 02 FB 01],
					[MTK_LCM_CMD_TYPE_HEX_WRITE_BUFFER 02 03 00],
					[MTK_LCM_CMD_TYPE_HEX_WRITE_BUFFER 02 04 7C],
					[MTK_LCM_CMD_TYPE_HEX_WRITE_BUFFER 02 08 21],
					[MTK_LCM_CMD_TYPE_HEX_WRITE_BUFFER 02 15 01],
					[MTK_LCM_CMD_TYPE_HEX_WRITE_BUFFER 02 74 AF],
					[MTK_LCM_CMD_TYPE_HEX_WRITE_BUFFER 02 81 0F],
					[MTK_LCM_CMD_TYPE_HEX_WRITE_BUFFER 02 83 04],
					[MTK_LCM_CMD_TYPE_HEX_WRITE_BUFFER 02 85 01],
					[MTK_LCM_CMD_TYPE_HEX_WRITE_BUFFER 02 87 01],
					[MTK_LCM_CMD_TYPE_HEX_WRITE_BUFFER 02 88 03],
					[MTK_LCM_CMD_TYPE_HEX_WRITE_BUFFER 02 8A 1A],
					[MTK_LCM_CMD_TYPE_HEX_WRITE_BUFFER 02 8B 11],
					[MTK_LCM_CMD_TYPE_HEX_WRITE_BUFFER 02 8C 24],
					[MTK_LCM_CMD_TYPE_HEX_WRITE_BUFFER 02 8E 42],
					[MTK_LCM_CMD_TYPE_HEX_WRITE_BUFFER 02 8F 11],
					[MTK_LCM_CMD_TYPE_HEX_WRITE_BUFFER 02 90 11],
					[MTK_LCM_CMD_TYPE_HEX_WRITE_BUFFER 02 91 11],
					[MTK_LCM_CMD_TYPE_HEX_WRITE_BUFFER 02 9A 80],
					[MTK_LCM_CMD_TYPE_HEX_WRITE_BUFFER 02 9B 42],
					[MTK_LCM_CMD_TYPE_HEX_WRITE_BUFFER 02 9C 00],
					[MTK_LCM_CMD_TYPE_HEX_WRITE_BUFFER 02 9D 00],
					[MTK_LCM_CMD_TYPE_HEX_WRITE_BUFFER 02 9E 00],
					[MTK_LCM_CMD_TYPE_HEX_WRITE_BUFFER 02 FF 27],
					[MTK_LCM_CMD_TYPE_HEX_WRITE_BUFFER 02 FB 01],
					[MTK_LCM_CMD_TYPE_HEX_WRITE_BUFFER 02 20 81],
					[MTK_LCM_CMD_TYPE_HEX_WRITE_BUFFER 02 21 82],
					[MTK_LCM_CMD_TYPE_HEX_WRITE_BUFFER 02 25 81],
					[MTK_LCM_CMD_TYPE_HEX_WRITE_BUFFER 02 26 AB],
					[MTK_LCM_CMD_TYPE_HEX_WRITE_BUFFER 02 6E 01],
					[MTK_LCM_CMD_TYPE_HEX_WRITE_BUFFER 02 6F 00],
					[MTK_LCM_CMD_TYPE_HEX_WRITE_BUFFER 02 70 00],
					[MTK_LCM_CMD_TYPE_HEX_WRITE_BUFFER 02 71 00],
					[MTK_LCM_CMD_TYPE_HEX_WRITE_BUFFER 02 72 00],
					[MTK_LCM_CMD_TYPE_HEX_WRITE_BUFFER 02 73 04],
					[MTK_LCM_CMD_TYPE_HEX_WRITE_BUFFER 02 74 21],
					[MTK_LCM_CMD_TYPE_HEX_WRITE_BUFFER 02 75 03],
					[MTK_LCM_CMD_TYPE_HEX_WRITE_BUFFER 02 76 00],
					[MTK_LCM_CMD_TYPE_HEX_WRITE_BUFFER 02 77 00],
					[MTK_LCM_CMD_TYPE_HEX_WRITE_BUFFER 02 7D 09],
					[MTK_LCM_CMD_TYPE_HEX_WRITE_BUFFER 02 7E 25],
					[MTK_LCM_CMD_TYPE_HEX_WRITE_BUFFER 02 80 24],
					[MTK_LCM_CMD_TYPE_HEX_WRITE_BUFFER 02 82 09],
					[MTK_LCM_CMD_TYPE_HEX_WRITE_BUFFER 02 83 25],
					[MTK_LCM_CMD_TYPE_HEX_WRITE_BUFFER 02 88 01],
					[MTK_LCM_CMD_TYPE_HEX_WRITE_BUFFER 02 89 10],
					[MTK_LCM_CMD_TYPE_HEX_WRITE_BUFFER 02 B7 04],
					[MTK_LCM_CMD_TYPE_HEX_WRITE_BUFFER 02 FF 2A],
					[MTK_LCM_CMD_TYPE_HEX_WRITE_BUFFER 02 FB 01],
					[MTK_LCM_CMD_TYPE_HEX_WRITE_BUFFER 02 01 00],
					[MTK_LCM_CMD_TYPE_HEX_WRITE_BUFFER 02 05 00],
					[MTK_LCM_CMD_TYPE_HEX_WRITE_BUFFER 02 06 07],
					[MTK_LCM_CMD_TYPE_HEX_WRITE_BUFFER 02 08 0E],
					[MTK_LCM_CMD_TYPE_HEX_WRITE_BUFFER 02 0A 04],
					[MTK_LCM_CMD_TYPE_HEX_WRITE_BUFFER 02 0B 01],
					[MTK_LCM_CMD_TYPE_HEX_WRITE_BUFFER 02 0C 09],
					[MTK_LCM_CMD_TYPE_HEX_WRITE_BUFFER 02 11 EA],
					[MTK_LCM_CMD_TYPE_HEX_WRITE_BUFFER 02 15 07],
					[MTK_LCM_CMD_TYPE_HEX_WRITE_BUFFER 02 16 C3],
					[MTK_LCM_CMD_TYPE_HEX_WRITE_BUFFER 02 1A 40],
					[MTK_LCM_CMD_TYPE_HEX_WRITE_BUFFER 02 1B 0A],
					[MTK_LCM_CMD_TYPE_HEX_WRITE_BUFFER 02 1D 0A],
					[MTK_LCM_CMD_TYPE_HEX_WRITE_BUFFER 02 1E 42],
					[MTK_LCM_CMD_TYPE_HEX_WRITE_BUFFER 02 1F 42],
					[MTK_LCM_CMD_TYPE_HEX_WRITE_BUFFER 02 20 42],
					[MTK_LCM_CMD_TYPE_HEX_WRITE_BUFFER 02 28 08],
					[MTK_LCM_CMD_TYPE_HEX_WRITE_BUFFER 02 37 70],
					[MTK_LCM_CMD_TYPE_HEX_WRITE_BUFFER 02 FF D0],
					[MTK_LCM_CMD_TYPE_HEX_WRITE_BUFFER 02 FB 01],
					[MTK_LCM_CMD_TYPE_HEX_WRITE_BUFFER 02 B0 00],
					[MTK_LCM_CMD_TYPE_HEX_WRITE_BUFFER 02 FF 20],
					[MTK_LCM_CMD_TYPE_HEX_WRITE_BUFFER 02 FB 01],
					[MTK_LCM_CMD_TYPE_HEX_WRITE_BUFFER 02 01 66],
					[MTK_LCM_CMD_TYPE_HEX_WRITE_BUFFER 02 F2 64],
					[MTK_LCM_CMD_TYPE_HEX_WRITE_BUFFER 02 F4 64],
					[MTK_LCM_CMD_TYPE_HEX_WRITE_BUFFER 02 F6 64],
					[MTK_LCM_CMD_TYPE_HEX_WRITE_BUFFER 02 F8 64],
					[MTK_LCM_CMD_TYPE_HEX_WRITE_BUFFER 02 FF 24],
					[MTK_LCM_CMD_TYPE_HEX_WRITE_BUFFER 02 FB 01],
					[MTK_LCM_CMD_TYPE_HEX_WRITE_BUFFER 02 C9 00],
					[MTK_LCM_CMD_TYPE_HEX_WRITE_BUFFER 02 FF E0],
					[MTK_LCM_CMD_TYPE_HEX_WRITE_BUFFER 02 FB 01],
					[MTK_LCM_CMD_TYPE_HEX_WRITE_BUFFER 02 25 02],
					[MTK_LCM_CMD_TYPE_HEX_WRITE_BUFFER 02 4E 02],
					[MTK_LCM_CMD_TYPE_HEX_WRITE_BUFFER 02 85 32],
					[MTK_LCM_CMD_TYPE_HEX_WRITE_BUFFER 02 FF F0],
					[MTK_LCM_CMD_TYPE_HEX_WRITE_BUFFER 02 FB 01],
					[MTK_LCM_CMD_TYPE_HEX_WRITE_BUFFER 02 5A 00],
					[MTK_LCM_CMD_TYPE_HEX_WRITE_BUFFER 02 A0 08],
					[MTK_LCM_CMD_TYPE_HEX_WRITE_BUFFER 02 FF D0],
					[MTK_LCM_CMD_TYPE_HEX_WRITE_BUFFER 02 FB 01],
					[MTK_LCM_CMD_TYPE_HEX_WRITE_BUFFER 02 09 AD],
					[MTK_LCM_CMD_TYPE_HEX_WRITE_BUFFER 02 FF 10],
					[MTK_LCM_CMD_TYPE_HEX_WRITE_BUFFER 02 51 FF],
					[MTK_LCM_CMD_TYPE_HEX_WRITE_BUFFER 02 53 24],
					[MTK_LCM_CMD_TYPE_HEX_WRITE_BUFFER 02 35 00],
					[MTK_LCM_CMD_TYPE_HEX_WRITE_BUFFER 02 FF 10],
					[MTK_LCM_CMD_TYPE_HEX_WRITE_BUFFER 01 11],
					[MTK_LCM_UTIL_TYPE_HEX_MDELAY 01 64],
					[MTK_LCM_CMD_TYPE_HEX_WRITE_BUFFER 01 29],
					[MTK_LCM_UTIL_TYPE_HEX_MDELAY 01 14],
					[MTK_LCM_TYPE_HEX_END];

				unprepare_table =
					[MTK_LCM_CMD_TYPE_HEX_WRITE_BUFFER 02 28 00],
					[MTK_LCM_UTIL_TYPE_HEX_MDELAY 01 32],
					[MTK_LCM_CMD_TYPE_HEX_WRITE_BUFFER 02 10 00],
					[MTK_LCM_UTIL_TYPE_HEX_MDELAY 01 96],
					[MTK_LCM_TYPE_HEX_END];

				set_display_on_table =
					[MTK_LCM_PHASE_TYPE_HEX_START 02],
						[MTK_LCM_PHASE_HEX_LK],
						[MTK_LCM_PHASE_HEX_LK_DISPLAY_ON_DELAY],
					[MTK_LCM_UTIL_TYPE_HEX_TDELAY 01 c8],
					[MTK_LCM_CMD_TYPE_HEX_WRITE_BUFFER 01 29],
					[MTK_LCM_UTIL_TYPE_HEX_MDELAY 01 64],
					[MTK_LCM_PHASE_TYPE_HEX_END 02],
						[MTK_LCM_PHASE_HEX_LK],
						[MTK_LCM_PHASE_HEX_LK_DISPLAY_ON_DELAY],
					[MTK_LCM_TYPE_HEX_END];

				lcm_update_table = [MTK_LCM_LK_TYPE_HEX_PREPARE_PARAM_COUNT 01 03],
						[MTK_LCM_LK_TYPE_HEX_PREPARE_PARAM 05],
						[00 00 05 39 02],
					/*2a is of data[1] bit0 */
					[MTK_LCM_LK_TYPE_HEX_PREPARE_PARAM_FIX_BIT 03 01 00 2a],
					/*x0_msb is of data[1] bit8 */
					[MTK_LCM_LK_TYPE_HEX_PREPARE_PARAM_X0_MSB_BIT 03 01 08 00],
					/*x0_lsb is of data[1] bit16 */
					[MTK_LCM_LK_TYPE_HEX_PREPARE_PARAM_X0_LSB_BIT 03 01 10 00],
					/*x1_msb is of data[1] bit24 */
					[MTK_LCM_LK_TYPE_HEX_PREPARE_PARAM_X1_MSB_BIT 03 01 18 00],
					/*x0_lsb is of data[2] bit0 */
					[MTK_LCM_LK_TYPE_HEX_PREPARE_PARAM_X1_LSB_BIT 03 02 00 00],
					[MTK_LCM_LK_TYPE_HEX_WRITE_PARAM 00],
					[MTK_LCM_LK_TYPE_HEX_PREPARE_PARAM_COUNT 01 03],
					[MTK_LCM_LK_TYPE_HEX_PREPARE_PARAM 05],
						[00 00 05 39 02],
					/*2b is of data[1] bit0 */
					[MTK_LCM_LK_TYPE_HEX_PREPARE_PARAM_FIX_BIT 03 01 00 2b],
					/*y0_msb is of data[1] bit8 */
					[MTK_LCM_LK_TYPE_HEX_PREPARE_PARAM_Y0_MSB_BIT 03 01 08 00],
					/*y0_lsb is of data[1] bit16 */
					[MTK_LCM_LK_TYPE_HEX_PREPARE_PARAM_Y0_LSB_BIT 03 01 10 00],
					/*y1_msb is of data[1] bit24 */
					[MTK_LCM_LK_TYPE_HEX_PREPARE_PARAM_Y1_MSB_BIT 03 01 18 00],
					/*y0_lsb is of data[2] bit0 */
					[MTK_LCM_LK_TYPE_HEX_PREPARE_PARAM_Y1_LSB_BIT 03 02 00 00],
					[MTK_LCM_LK_TYPE_HEX_WRITE_PARAM 00],
					[MTK_LCM_LK_TYPE_HEX_PREPARE_PARAM_COUNT 01 01],
					[MTK_LCM_LK_TYPE_HEX_PREPARE_PARAM 05],
						[00 00 2c 39 09],
					[MTK_LCM_LK_TYPE_HEX_WRITE_PARAM_UNFORCE 00],
					[MTK_LCM_TYPE_HEX_END];

				set_backlight_mask = <0xfff>;
				set_backlight_cmdq_table =
					/* runtime input count, data id*/
					[MTK_LCM_CB_TYPE_HEX_RUNTIME_INPUT_MULTIPLE 07 02 01 02],
						[03 51 0F FF],/*data count, data mask or value*/
					[MTK_LCM_TYPE_HEX_END];

				set_aod_light_mask = <0xfff>;
				set_aod_light_table;

				ata_id_value_data;
				ata_check_table;

				compare_id_value_data = [55];
				compare_id_table = [MTK_LCM_UTIL_TYPE_HEX_RESET 01 01],
					[MTK_LCM_UTIL_TYPE_HEX_MDELAY 01 0a],
					[MTK_LCM_UTIL_TYPE_HEX_RESET 01 00],
					[MTK_LCM_UTIL_TYPE_HEX_MDELAY 01 0a],
					[MTK_LCM_UTIL_TYPE_HEX_RESET 01 01],
					[MTK_LCM_UTIL_TYPE_HEX_MDELAY 01 0a],
					[MTK_LCM_LK_TYPE_HEX_PREPARE_PARAM_COUNT 01 01],
					[MTK_LCM_LK_TYPE_HEX_PREPARE_PARAM 05 00 00 10 05 00],
					[MTK_LCM_LK_TYPE_HEX_WRITE_PARAM 00],
					[MTK_LCM_UTIL_TYPE_HEX_MDELAY 01 14],
					[MTK_LCM_LK_TYPE_HEX_PREPARE_PARAM_COUNT 01 01],
					[MTK_LCM_LK_TYPE_HEX_PREPARE_PARAM 05 00 00 01 37 00],
					[MTK_LCM_LK_TYPE_HEX_WRITE_PARAM 00],
					[MTK_LCM_CMD_TYPE_HEX_READ_BUFFER 03 00 01 DA],
					[MTK_LCM_LK_TYPE_HEX_PREPARE_PARAM_COUNT 01 01],
					[MTK_LCM_LK_TYPE_HEX_PREPARE_PARAM 05 00 f0 ff 15 00],
					[MTK_LCM_LK_TYPE_HEX_WRITE_PARAM 00],
					[MTK_LCM_UTIL_TYPE_HEX_MDELAY 01 02],
					[MTK_LCM_LK_TYPE_HEX_PREPARE_PARAM_COUNT 01 01],
					[MTK_LCM_LK_TYPE_HEX_PREPARE_PARAM 05 00 00 01 37 00],
					[MTK_LCM_LK_TYPE_HEX_WRITE_PARAM 00],
					[MTK_LCM_UTIL_TYPE_HEX_MDELAY 01 02],
					[MTK_LCM_TYPE_HEX_END];

				doze_enable_start_table;

				doze_enable_table;

				doze_disable_table;

				doze_area_table;

				doze_post_disp_on_table;

				hbm_set_cmdq_switch_id;
				hbm_set_cmdq_switch_on;
				hbm_set_cmdq_switch_off;
				hbm_set_cmdq_table;

				/* fps switch cmd for high frame rate feature */
				lcm-ops-dsi-fps-switch-after-poweron {
					compatible =
						"mediatek,lcm-ops-dsi-fps-switch-after-poweron";
					fps-switch-2-1080-2340-60_table;

					fps-switch-1-1080-2340-90_table;

					fps-switch-0-1080-2340-120_table;
				};

				lcm-ops-dsi-fps-switch-before-powerdown {
					compatible =
						"mediatek,lcm-ops-dsi-fps-switch-before-powerdown";
					fps-switch-2-1080-2340-60_table;

					fps-switch-1-1080-2340-90_table;

					fps-switch-0-1080-2340-120_table;
				};
			};
		};
	};
};

